VERSION ""

NS_ :

BS_:

BU_: BADNODE FAKEDEVICE WRONGMODULE

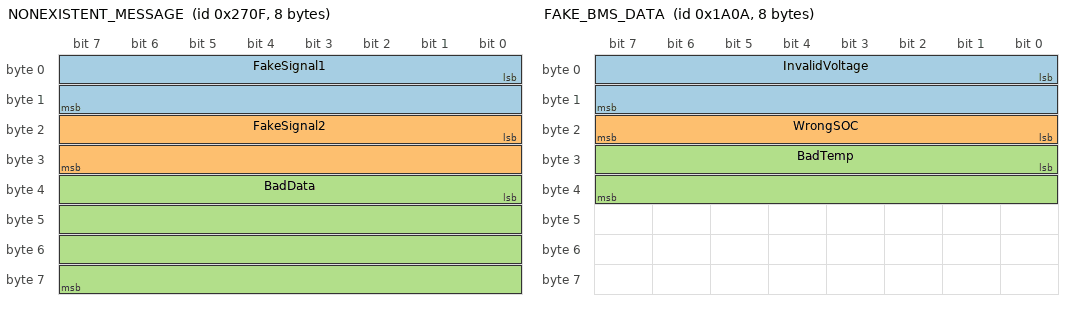
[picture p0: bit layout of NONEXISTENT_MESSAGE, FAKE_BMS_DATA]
BO_ 9999 NONEXISTENT_MESSAGE: 8 BADNODE
 SG_ FakeSignal1 : 0|16@1+ (1,0) [0|65535] "" FAKEDEVICE
 SG_ FakeSignal2 : 16|16@1+ (0.1,-100) [-100|6453.5] "C" FAKEDEVICE
 SG_ BadData : 32|32@1- (1,0) [-2147483648|2147483647] "" BADNODE

BO_ 8888 WRONG_VCU_MESSAGE: 8 WRONGMODULE
 SG_ IncorrectPedal : 0|8@1+ (0.5,0) [0|127.5] "%" FAKEDEVICE
 SG_ WrongState : 8|8@1+ (1,0) [0|255] "" WRONGMODULE

BO_ 7777 INVALID_INVERTER: 8 BADNODE
 SG_ BogusTemp : 0|16@1+ (0.1,-40) [-40|6513.5] "C" FAKEDEVICE
 SG_ FakeCurrent : 16|16@1- (0.1,0) [-3276.8|3276.7] "A" WRONGMODULE

BO_ 6666 FAKE_BMS_DATA: 8 BADNODE
 SG_ InvalidVoltage : 0|16@1+ (0.001,0) [0|65.535] "V" FAKEDEVICE
 SG_ WrongSOC : 16|8@1+ (1,0) [0|100] "%" WRONGMODULE
 SG_ BadTemp : 24|16@1+ (0.1,-273.15) [-273.15|6280.35] "K" BADNODE

CM_ "This is a BAD DBC file for testing. None of these message IDs or signals match real CAN messages.";
CM_ BO_ 9999 "Nonexistent message - ID 9999 should never appear on the bus";
CM_ BO_ 8888 "Wrong VCU message with incorrect signals";
CM_ BO_ 7777 "Invalid inverter message for testing";
CM_ BO_ 6666 "Fake BMS data that won't decode real messages";
